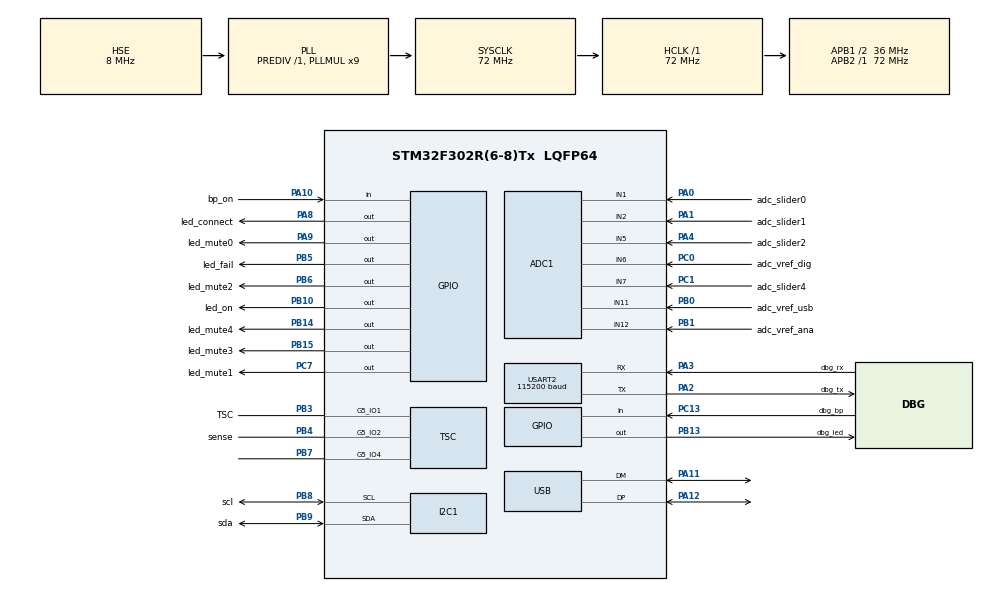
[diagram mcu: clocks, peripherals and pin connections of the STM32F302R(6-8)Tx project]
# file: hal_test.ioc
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ADC1.Channel-0\#ChannelRegularConversion=ADC_CHANNEL_TEMPSENSOR
ADC1.NbrOfConversionFlag=1
ADC1.Offset-0\#ChannelRegularConversion=0
ADC1.OffsetNumber-0\#ChannelRegularConversion=ADC_OFFSET_NONE
ADC1.Rank-0\#ChannelRegularConversion=1
ADC1.SamplingTime-0\#ChannelRegularConversion=ADC_SAMPLETIME_1CYCLE_5
ADC1.master=1
I2C1.Timing=0x00201D2B
Mcu.Family=STM32F3
Mcu.Name=STM32F302R(6-8)Tx
Mcu.Package=LQFP64
NVIC.PriorityGroup=NVIC_PRIORITYGROUP_4
PA0.GPIO_Label=adc_slider0
PA0.Mode=IN1-Differential
PA0.Signal=ADC1_IN1
PA1.GPIO_Label=adc_slider1
PA1.Mode=IN1-Differential
PA1.Signal=ADC1_IN2
PA10.GPIO_Label=bp_on
PA10.Signal=GPIO_Input
PA11.Mode=Device
PA11.Signal=USB_DM
PA12.Mode=Device
PA12.Signal=USB_DP
PA13.Mode=Serial_Wire
PA13.Signal=SYS_JTMS-SWDIO
PA14.Mode=Serial_Wire
PA14.Signal=SYS_JTCK-SWCLK
PA2.GPIO_Label=dbg_tx
PA2.Mode=Asynchronous
PA2.Signal=USART2_TX
PA3.GPIO_Label=dbg_rx
PA3.Mode=Asynchronous
PA3.Signal=USART2_RX
PA4.GPIO_Label=adc_slider2
PA4.Mode=IN5-Single-Ended
PA4.Signal=ADC1_IN5
PA8.GPIO_Label=led_connect
PA8.Signal=GPIO_Output
PA9.GPIO_Label=led_mute0
PA9.Signal=GPIO_Output
PB0.GPIO_Label=adc_vref_usb
PB0.Mode=IN11-Single-Ended
PB0.Signal=ADC1_IN11
PB1.GPIO_Label=adc_vref_ana
PB1.Mode=IN12-Single-Ended
PB1.Signal=ADC1_IN12
PB10.GPIO_Label=led_on
PB10.Signal=GPIO_Output
PB13.GPIO_Label=dbg_led
PB13.Signal=GPIO_Output
PB14.GPIO_Label=led_mute4
PB14.Signal=GPIO_Output
PB15.GPIO_Label=led_mute3
PB15.Signal=GPIO_Output
PB3.GPIO_Label=TSC
PB3.Mode=G5_IO1-Channel
PB3.Signal=TSC_G5_IO1
PB4.GPIO_Label=sense
PB4.Mode=G5_IO2-Sampling
PB4.Signal=TSC_G5_IO2
PB5.GPIO_Label=led_fail
PB5.Signal=GPIO_Output
PB6.GPIO_Label=led_mute2
PB6.Signal=GPIO_Output
PB7.Mode=G5_IO4-Channel
PB7.Signal=TSC_G5_IO4
PB8.GPIO_Label=scl
PB8.Mode=I2C
PB8.Signal=I2C1_SCL
PB9.GPIO_Label=sda
PB9.Mode=I2C
PB9.Signal=I2C1_SDA
PC0.GPIO_Label=adc_vref_dig
PC0.Signal=ADCx_IN6
PC1.GPIO_Label=adc_slider4
PC1.Signal=ADCx_IN7
PC13.GPIO_Label=dbg_bp
PC13.Signal=GPIO_Input
PC7.GPIO_Label=led_mute1
PC7.Signal=GPIO_Output
PF0-OSC_IN.Mode=HSE-External-Clock-Source
PF0-OSC_IN.Signal=RCC_OSC_IN
ProjectManager.HeapSize=0x200
ProjectManager.StackSize=0x400
ProjectManager.TargetToolchain=STM32CubeIDE
RCC.AHBFreq_Value=72000000
RCC.APB1CLKDivider=RCC_HCLK_DIV2
RCC.APB1Freq_Value=36000000
RCC.APB1TimFreq_Value=72000000
RCC.APB2Freq_Value=72000000
RCC.APB2TimFreq_Value=72000000
RCC.CortexFreq_Value=72000000
RCC.EnbaleCSS=true
RCC.HCLKFreq_Value=72000000
RCC.HSE_VALUE=8000000
RCC.HSI_VALUE=8000000
RCC.LSE_VALUE=32768
RCC.PLLMUL=RCC_PLL_MUL9
RCC.PRESCALERUSB=RCC_USBCLKSOURCE_PLL_DIV1_5
RCC.SYSCLKFreq_VALUE=72000000
RCC.SYSCLKSourceVirtual=RCC_SYSCLKSOURCE_PLLCLK
RCC.USBFreq_Value=48000000
SH.ADCx_IN6.0=ADC1_IN6,IN6-Single-Ended
SH.ADCx_IN7.0=ADC1_IN7,IN7-Single-Ended
TSC.ChannelIOs-G5_IO1-Channel=TSC_GROUP5_IO1
TSC.ChannelIOs-G5_IO4-Channel=TSC_GROUP5_IO4
TSC.SamplingIOs-G5_IO2-Sampling=TSC_GROUP5_IO2
USART2.BaudRate=115200
USART2.VirtualMode-Asynchronous=VM_ASYNC
USB.low_power_enable=DISABLE
VP_ADC1_TempSens_Input.Mode=IN-TempSens
VP_ADC1_Vbat_Input.Mode=IN-Vbat
VP_ADC1_Vref_Input.Mode=IN-Vrefint
board=custom

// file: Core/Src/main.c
/* USER CODE BEGIN Header */
/**
  ******************************************************************************
  * @file           : main.c
  * @brief          : Main program body
  ******************************************************************************
  * @attention
  *
  * Copyright (c) 2025 STMicroelectronics.
  * All rights reserved.
  *
  * This software is licensed under terms that can be found in the LICENSE file
  * in the root directory of this software component.
  * If no LICENSE file comes with this software, it is provided AS-IS.
  *
  ******************************************************************************
  */
/* USER CODE END Header */
#include "main.h"

/* USER CODE BEGIN Includes */
#include "hal/leds.hpp"

/* USER CODE END Includes */

ADC_HandleTypeDef hadc1;

I2C_HandleTypeDef hi2c1;

TSC_HandleTypeDef htsc;

UART_HandleTypeDef huart2;

PCD_HandleTypeDef hpcd_USB_FS;

void SystemClock_Config(void);
static void MX_GPIO_Init(void);
static void MX_ADC1_Init(void);
static void MX_I2C1_Init(void);
static void MX_TSC_Init(void);
static void MX_USART2_UART_Init(void);
static void MX_USB_PCD_Init(void);

int main(void)
{

  /* MCU Configuration--------------------------------------------------------*/

  /* Reset of all peripherals, Initializes the Flash interface and the Systick. */
  HAL_Init();

  /* Configure the system clock */
  SystemClock_Config();

  /* Initialize all configured peripherals */
  MX_GPIO_Init();
  MX_ADC1_Init();
  MX_I2C1_Init();
  MX_TSC_Init();
  MX_USART2_UART_Init();
  MX_USB_PCD_Init();

  /* Infinite loop */
  /* USER CODE BEGIN WHILE */
  const uint8_t *data = (uint8_t*)"Hello World !\n\r";

  while (1)
  {
    /* USER CODE END WHILE */

    /* USER CODE BEGIN 3 */

	  HAL_UART_Transmit(&huart2, data, 15, 100);
	  debug_Toggle_Led();
	  HAL_Delay(1000);
  }
  /* USER CODE END 3 */
}

void SystemClock_Config(void)
{
  RCC_OscInitTypeDef RCC_OscInitStruct = {0};
  RCC_ClkInitTypeDef RCC_ClkInitStruct = {0};
  RCC_PeriphCLKInitTypeDef PeriphClkInit = {0};

  /** Initializes the RCC Oscillators according to the specified parameters
  * in the RCC_OscInitTypeDef structure.
  */
  RCC_OscInitStruct.OscillatorType = RCC_OSCILLATORTYPE_HSI|RCC_OSCILLATORTYPE_HSE;
  RCC_OscInitStruct.HSEState = RCC_HSE_BYPASS;
  RCC_OscInitStruct.HSEPredivValue = RCC_HSE_PREDIV_DIV1;
  RCC_OscInitStruct.HSIState = RCC_HSI_ON;
  RCC_OscInitStruct.HSICalibrationValue = RCC_HSICALIBRATION_DEFAULT;
  RCC_OscInitStruct.PLL.PLLState = RCC_PLL_ON;
  RCC_OscInitStruct.PLL.PLLSource = RCC_PLLSOURCE_HSE;
  RCC_OscInitStruct.PLL.PLLMUL = RCC_PLL_MUL9;
  if (HAL_RCC_OscConfig(&RCC_OscInitStruct) != HAL_OK)
  {
    Error_Handler();
  }

  /** Initializes the CPU, AHB and APB buses clocks
  */
  RCC_ClkInitStruct.ClockType = RCC_CLOCKTYPE_HCLK|RCC_CLOCKTYPE_SYSCLK
                              |RCC_CLOCKTYPE_PCLK1|RCC_CLOCKTYPE_PCLK2;
  RCC_ClkInitStruct.SYSCLKSource = RCC_SYSCLKSOURCE_PLLCLK;
  RCC_ClkInitStruct.AHBCLKDivider = RCC_SYSCLK_DIV1;
  RCC_ClkInitStruct.APB1CLKDivider = RCC_HCLK_DIV2;
  RCC_ClkInitStruct.APB2CLKDivider = RCC_HCLK_DIV1;

  if (HAL_RCC_ClockConfig(&RCC_ClkInitStruct, FLASH_LATENCY_2) != HAL_OK)
  {
    Error_Handler();
  }
  PeriphClkInit.PeriphClockSelection = RCC_PERIPHCLK_USB|RCC_PERIPHCLK_I2C1
                              |RCC_PERIPHCLK_ADC1;
  PeriphClkInit.I2c1ClockSelection = RCC_I2C1CLKSOURCE_HSI;
  PeriphClkInit.USBClockSelection = RCC_USBCLKSOURCE_PLL_DIV1_5;
  PeriphClkInit.Adc1ClockSelection = RCC_ADC1PLLCLK_DIV1;

  if (HAL_RCCEx_PeriphCLKConfig(&PeriphClkInit) != HAL_OK)
  {
    Error_Handler();
  }

  /** Enables the Clock Security System
  */
  HAL_RCC_EnableCSS();
}

static void MX_ADC1_Init(void)
{

  ADC_ChannelConfTypeDef sConfig = {0};

  /** Common config
  */
  hadc1.Instance = ADC1;
  hadc1.Init.ClockPrescaler = ADC_CLOCK_ASYNC_DIV1;
  hadc1.Init.Resolution = ADC_RESOLUTION_12B;
  hadc1.Init.ScanConvMode = ADC_SCAN_DISABLE;
  hadc1.Init.ContinuousConvMode = DISABLE;
  hadc1.Init.DiscontinuousConvMode = DISABLE;
  hadc1.Init.ExternalTrigConvEdge = ADC_EXTERNALTRIGCONVEDGE_NONE;
  hadc1.Init.ExternalTrigConv = ADC_SOFTWARE_START;
  hadc1.Init.DataAlign = ADC_DATAALIGN_RIGHT;
  hadc1.Init.NbrOfConversion = 1;
  hadc1.Init.DMAContinuousRequests = DISABLE;
  hadc1.Init.EOCSelection = ADC_EOC_SINGLE_CONV;
  hadc1.Init.LowPowerAutoWait = DISABLE;
  hadc1.Init.Overrun = ADC_OVR_DATA_OVERWRITTEN;
  if (HAL_ADC_Init(&hadc1) != HAL_OK)
  {
    Error_Handler();
  }

  /** Configure Regular Channel
  */
  sConfig.Channel = ADC_CHANNEL_TEMPSENSOR;
  sConfig.Rank = ADC_REGULAR_RANK_1;
  sConfig.SingleDiff = ADC_SINGLE_ENDED;
  sConfig.SamplingTime = ADC_SAMPLETIME_1CYCLE_5;
  sConfig.OffsetNumber = ADC_OFFSET_NONE;
  sConfig.Offset = 0;
  if (HAL_ADC_ConfigChannel(&hadc1, &sConfig) != HAL_OK)
  {
    Error_Handler();
  }

}

static void MX_I2C1_Init(void)
{

  hi2c1.Instance = I2C1;
  hi2c1.Init.Timing = 0x00201D2B;
  hi2c1.Init.OwnAddress1 = 0;
  hi2c1.Init.AddressingMode = I2C_ADDRESSINGMODE_7BIT;
  hi2c1.Init.DualAddressMode = I2C_DUALADDRESS_DISABLE;
  hi2c1.Init.OwnAddress2 = 0;
  hi2c1.Init.OwnAddress2Masks = I2C_OA2_NOMASK;
  hi2c1.Init.GeneralCallMode = I2C_GENERALCALL_DISABLE;
  hi2c1.Init.NoStretchMode = I2C_NOSTRETCH_DISABLE;
  if (HAL_I2C_Init(&hi2c1) != HAL_OK)
  {
    Error_Handler();
  }

  /** Configure Analogue filter
  */
  if (HAL_I2CEx_ConfigAnalogFilter(&hi2c1, I2C_ANALOGFILTER_ENABLE) != HAL_OK)
  {
    Error_Handler();
  }

  /** Configure Digital filter
  */
  if (HAL_I2CEx_ConfigDigitalFilter(&hi2c1, 0) != HAL_OK)
  {
    Error_Handler();
  }

}

static void MX_TSC_Init(void)
{

  /** Configure the TSC peripheral
  */
  htsc.Instance = TSC;
  htsc.Init.CTPulseHighLength = TSC_CTPH_2CYCLES;
  htsc.Init.CTPulseLowLength = TSC_CTPL_2CYCLES;
  htsc.Init.SpreadSpectrum = DISABLE;
  htsc.Init.SpreadSpectrumDeviation = 1;
  htsc.Init.SpreadSpectrumPrescaler = TSC_SS_PRESC_DIV1;
  htsc.Init.PulseGeneratorPrescaler = TSC_PG_PRESC_DIV4;
  htsc.Init.MaxCountValue = TSC_MCV_8191;
  htsc.Init.IODefaultMode = TSC_IODEF_OUT_PP_LOW;
  htsc.Init.SynchroPinPolarity = TSC_SYNC_POLARITY_FALLING;
  htsc.Init.AcquisitionMode = TSC_ACQ_MODE_NORMAL;
  htsc.Init.MaxCountInterrupt = DISABLE;
  htsc.Init.ChannelIOs = TSC_GROUP5_IO1|TSC_GROUP5_IO4;
  htsc.Init.ShieldIOs = 0;
  htsc.Init.SamplingIOs = TSC_GROUP5_IO2;
  if (HAL_TSC_Init(&htsc) != HAL_OK)
  {
    Error_Handler();
  }

}

static void MX_USART2_UART_Init(void)
{

  huart2.Instance = USART2;
  huart2.Init.BaudRate = 115200;
  huart2.Init.WordLength = UART_WORDLENGTH_8B;
  huart2.Init.StopBits = UART_STOPBITS_1;
  huart2.Init.Parity = UART_PARITY_NONE;
  huart2.Init.Mode = UART_MODE_TX_RX;
  huart2.Init.HwFlowCtl = UART_HWCONTROL_NONE;
  huart2.Init.OverSampling = UART_OVERSAMPLING_16;
  huart2.Init.OneBitSampling = UART_ONE_BIT_SAMPLE_DISABLE;
  huart2.AdvancedInit.AdvFeatureInit = UART_ADVFEATURE_NO_INIT;
  if (HAL_UART_Init(&huart2) != HAL_OK)
  {
    Error_Handler();
  }

}

static void MX_USB_PCD_Init(void)
{

  hpcd_USB_FS.Instance = USB;
  hpcd_USB_FS.Init.dev_endpoints = 8;
  hpcd_USB_FS.Init.speed = PCD_SPEED_FULL;
  hpcd_USB_FS.Init.phy_itface = PCD_PHY_EMBEDDED;
  hpcd_USB_FS.Init.low_power_enable = DISABLE;
  hpcd_USB_FS.Init.battery_charging_enable = DISABLE;
  if (HAL_PCD_Init(&hpcd_USB_FS) != HAL_OK)
  {
    Error_Handler();
  }

}

static void MX_GPIO_Init(void)
{
  GPIO_InitTypeDef GPIO_InitStruct = {0};

  /* GPIO Ports Clock Enable */
  __HAL_RCC_GPIOC_CLK_ENABLE();
  __HAL_RCC_GPIOF_CLK_ENABLE();
  __HAL_RCC_GPIOA_CLK_ENABLE();
  __HAL_RCC_GPIOB_CLK_ENABLE();

  /*Configure GPIO pin Output Level */
  HAL_GPIO_WritePin(GPIOB, led_on_Pin|dbg_led_Pin|led_mute4_Pin|led_mute3_Pin
                          |led_fail_Pin|led_mute2_Pin, GPIO_PIN_RESET);

  /*Configure GPIO pin Output Level */
  HAL_GPIO_WritePin(led_mute1_GPIO_Port, led_mute1_Pin, GPIO_PIN_RESET);

  /*Configure GPIO pin Output Level */
  HAL_GPIO_WritePin(GPIOA, led_connect_Pin|led_mute0_Pin, GPIO_PIN_RESET);

  /*Configure GPIO pin : dbg_bp_Pin */
  GPIO_InitStruct.Pin = dbg_bp_Pin;
  GPIO_InitStruct.Mode = GPIO_MODE_INPUT;
  GPIO_InitStruct.Pull = GPIO_NOPULL;
  HAL_GPIO_Init(dbg_bp_GPIO_Port, &GPIO_InitStruct);

  /*Configure GPIO pins : led_on_Pin dbg_led_Pin led_mute4_Pin led_mute3_Pin
                           led_fail_Pin led_mute2_Pin */
  GPIO_InitStruct.Pin = led_on_Pin|dbg_led_Pin|led_mute4_Pin|led_mute3_Pin
                          |led_fail_Pin|led_mute2_Pin;
  GPIO_InitStruct.Mode = GPIO_MODE_OUTPUT_PP;
  GPIO_InitStruct.Pull = GPIO_NOPULL;
  GPIO_InitStruct.Speed = GPIO_SPEED_FREQ_LOW;
  HAL_GPIO_Init(GPIOB, &GPIO_InitStruct);

  /*Configure GPIO pin : led_mute1_Pin */
  GPIO_InitStruct.Pin = led_mute1_Pin;
  GPIO_InitStruct.Mode = GPIO_MODE_OUTPUT_PP;
  GPIO_InitStruct.Pull = GPIO_NOPULL;
  GPIO_InitStruct.Speed = GPIO_SPEED_FREQ_LOW;
  HAL_GPIO_Init(led_mute1_GPIO_Port, &GPIO_InitStruct);

  /*Configure GPIO pins : led_connect_Pin led_mute0_Pin */
  GPIO_InitStruct.Pin = led_connect_Pin|led_mute0_Pin;
  GPIO_InitStruct.Mode = GPIO_MODE_OUTPUT_PP;
  GPIO_InitStruct.Pull = GPIO_NOPULL;
  GPIO_InitStruct.Speed = GPIO_SPEED_FREQ_LOW;
  HAL_GPIO_Init(GPIOA, &GPIO_InitStruct);

  /*Configure GPIO pin : bp_on_Pin */
  GPIO_InitStruct.Pin = bp_on_Pin;
  GPIO_InitStruct.Mode = GPIO_MODE_INPUT;
  GPIO_InitStruct.Pull = GPIO_NOPULL;
  HAL_GPIO_Init(bp_on_GPIO_Port, &GPIO_InitStruct);

}

void Error_Handler(void)
{
  __disable_irq();
  while (1)
  {
  }
}
